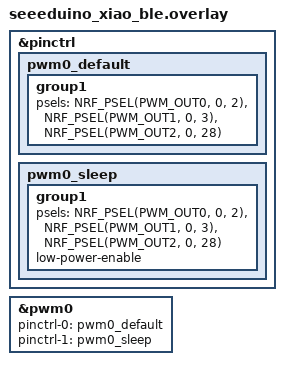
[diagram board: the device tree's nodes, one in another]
#include <dt-bindings/led/led.h>

&pinctrl {
    // Other Pinctrl definitions go here
    pwm0_default: pwm0_default {
        group1 {
            psels = <NRF_PSEL(PWM_OUT0, 0, 2)>, // LED 0
                    <NRF_PSEL(PWM_OUT1, 0, 3)>, // LED 1
                    <NRF_PSEL(PWM_OUT2, 0, 28)>; // LED 2
        };
    };
    pwm0_sleep: pwm0_sleep {
        group1 {
            psels = <NRF_PSEL(PWM_OUT0, 0, 2)>, // LED 0
                    <NRF_PSEL(PWM_OUT1, 0, 3)>, // LED 1
                    <NRF_PSEL(PWM_OUT2, 0, 28)>; // LED 2
            low-power-enable;
        };
    };
};

&pwm0 {
    status = "okay";
    pinctrl-0 = <&pwm0_default>;
    pinctrl-1 = <&pwm0_sleep>;
    pinctrl-names = "default", "sleep";
};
